VERSION ""

NS_ :

BS_:

BU_: Vector__XXX

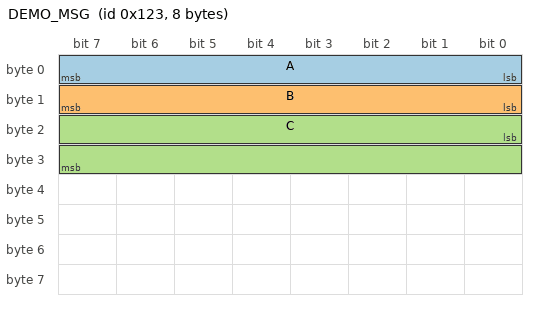
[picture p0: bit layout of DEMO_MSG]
BO_ 291 DEMO_MSG: 8 Vector__XXX
 SG_ A : 0|8@1+ (1,0) [0|255] "" Vector__XXX
 SG_ B : 8|8@1+ (1,0) [0|255] "" Vector__XXX
 SG_ C : 16|16@1+ (1,0) [0|65535] "" Vector__XXX
